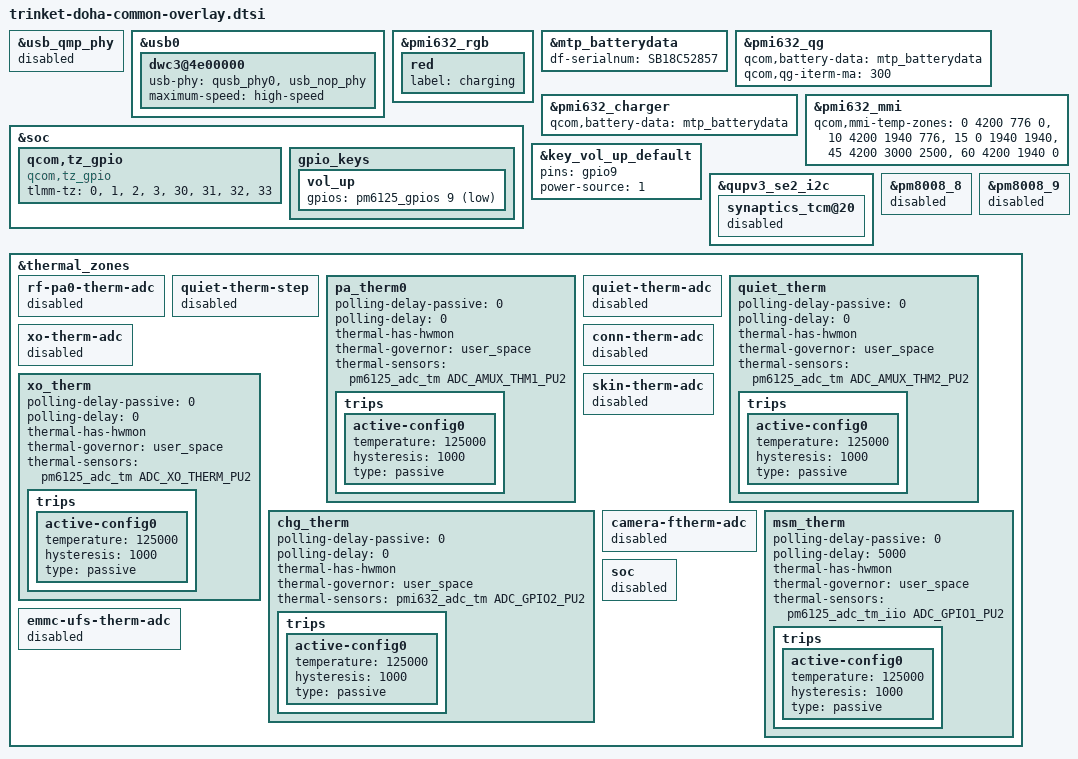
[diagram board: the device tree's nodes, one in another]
/* Copyright (c) 2018, The Linux Foundation. All rights reserved.
 *
 * This program is free software; you can redistribute it and/or modify
 * it under the terms of the GNU General Public License version 2 and
 * only version 2 as published by the Free Software Foundation.
 *
 * This program is distributed in the hope that it will be useful,
 * but WITHOUT ANY WARRANTY; without even the implied warranty of
 * MERCHANTABILITY or FITNESS FOR A PARTICULAR PURPOSE.  See the
 * GNU General Public License for more details.
 */

#include "trinket-moto-common-overlay.dtsi"
#include "doha-panel.dtsi"
#include "trinket-doha-audio-overlay.dtsi"
#include "trinket-doha-touch-overlay.dtsi"
#include "trinket-doha-camera-overlay.dtsi"
#include "trinket-doha-haptic-overlay.dtsi"
#include "trinket-doha-fps-overlay.dtsi"
#include "trinket-doha-nfc-overlay.dtsi"
#include "trinket-doha-sensor-overlay.dtsi"

&usb_qmp_phy {
	status = "disabled";
};

&usb0 {
	dwc3@4e00000 {
		usb-phy = <&qusb_phy0>, <&usb_nop_phy>;
		maximum-speed = "high-speed";
	};
};

&pmi632_rgb {
	red {
		label = "charging";
	};
};

&mtp_batterydata {
	df-serialnum = "SB18C52857";
};

&pmi632_qg {
	qcom,battery-data = <&mtp_batterydata>;
	qcom,qg-iterm-ma = <300>;
};

&pmi632_charger {
	qcom,battery-data = <&mtp_batterydata>;
};

&pmi632_mmi {
	qcom,mmi-temp-zones = <0 4200 776 0>,
			<10 4200 1940 776>,
			<15 0 1940 1940>,
			<45 4200 3000 2500>,
			<60 4200 1940 0>;
};

&soc {
	qcom,tz_gpio {
		compatible = "qcom,tz_gpio";
		tlmm-tz = <0>,
			<1>,
			<2>,
			<3>,
			<30>,
			<31>,
			<32>,
			<33>;
	};
};

&key_vol_up_default {
	pins = "gpio9";
	power-source = <1>;
};

&qupv3_se2_i2c {
	synaptics_tcm@20 {
		status = "disabled";
	};
};

&pm8008_8 {
	status = "disabled";
};

&pm8008_9 {
	status = "disabled";
};

&soc {
	gpio_keys {
		vol_up {
			gpios = <&pm6125_gpios 9 GPIO_ACTIVE_LOW>;
		};
	};
};

&thermal_zones {
	rf-pa0-therm-adc {
		status = "disabled";
	};

	quiet-therm-step {
		status = "disabled";
	};

	pa_therm0 {
		polling-delay-passive = <0>;
		polling-delay = <0>;
		thermal-has-hwmon;
		thermal-governor = "user_space";
		thermal-sensors = <&pm6125_adc_tm ADC_AMUX_THM1_PU2>;
		trips {
			active-config0 {
				temperature = <125000>;
				hysteresis = <1000>;
				type = "passive";
			};
		};
	};

	quiet-therm-adc {
		status = "disabled";
	};
	quiet_therm {
		polling-delay-passive = <0>;
		polling-delay = <0>;
		thermal-has-hwmon;
		thermal-governor = "user_space";
		thermal-sensors = <&pm6125_adc_tm ADC_AMUX_THM2_PU2>;
		trips {
			active-config0 {
				temperature = <125000>;
				hysteresis = <1000>;
				type = "passive";
			};
		};
	};

	xo-therm-adc {
		status = "disabled";
	};
	xo_therm {
		polling-delay-passive = <0>;
		polling-delay = <0>;
		thermal-has-hwmon;
		thermal-governor = "user_space";
		thermal-sensors = <&pm6125_adc_tm ADC_XO_THERM_PU2>;
		trips {
			active-config0 {
				temperature = <125000>;
				hysteresis = <1000>;
				type = "passive";
			};
		};
	};

	conn-therm-adc {
		status = "disabled";
	};

	skin-therm-adc {
		status = "disabled";
	};

	chg_therm {
		polling-delay-passive = <0>;
		polling-delay = <0>;
		thermal-has-hwmon;
		thermal-governor = "user_space";
		thermal-sensors = <&pmi632_adc_tm ADC_GPIO2_PU2>;
		trips {
			active-config0 {
				temperature = <125000>;
				hysteresis = <1000>;
				type = "passive";
			};
		};
	};

	camera-ftherm-adc {
		status = "disabled";
	};
	msm_therm {
		polling-delay-passive = <0>;
		polling-delay = <5000>;
		thermal-has-hwmon;
		thermal-governor = "user_space";
		thermal-sensors = <&pm6125_adc_tm_iio ADC_GPIO1_PU2>;
		trips {
			active-config0 {
				temperature = <125000>;
				hysteresis = <1000>;
				type = "passive";
			};
		};
	};

	emmc-ufs-therm-adc {
		status = "disabled";
	};

	soc {
		status = "disabled";
	};
};
